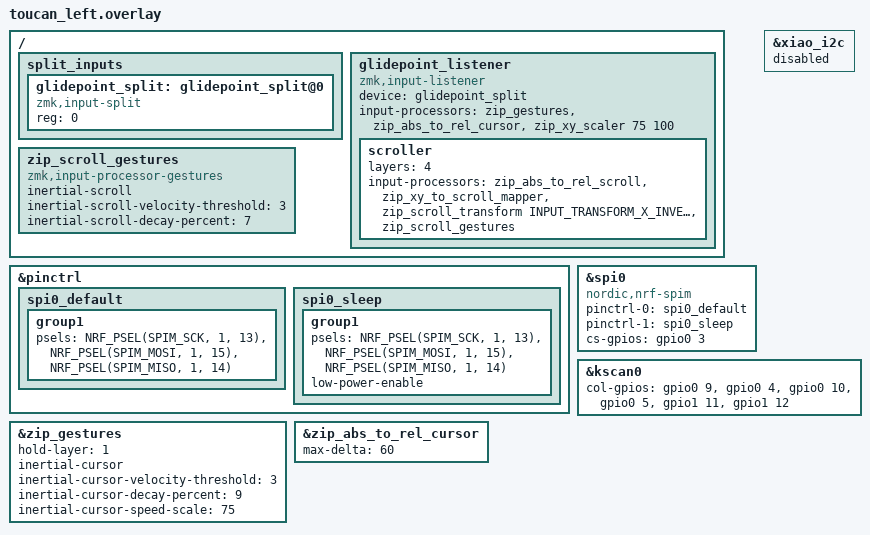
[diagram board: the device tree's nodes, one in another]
#include "toucan.dtsi"
#include <input/processors.dtsi>
#include <dt-bindings/zmk/input_transform.h>
#include <behaviors/input_processor_gestures.dtsi>
#include <behaviors/input_processor_abs_to_rel.dtsi>

&pinctrl {
    spi0_default: spi0_default {
        group1 {
            psels = <NRF_PSEL(SPIM_SCK, 1, 13)>,
                <NRF_PSEL(SPIM_MOSI, 1, 15)>,
                <NRF_PSEL(SPIM_MISO, 1, 14)>;
        };
    };

     spi0_sleep: spi0_sleep {
        group1 {
            psels = <NRF_PSEL(SPIM_SCK, 1, 13)>,
                    <NRF_PSEL(SPIM_MOSI, 1, 15)>,
                    <NRF_PSEL(SPIM_MISO, 1, 14)>;
            low-power-enable;
        };
    };

};

nice_view_spi: &spi0 {
   compatible = "nordic,nrf-spim";
   pinctrl-0 = <&spi0_default>;
   pinctrl-1 = <&spi0_sleep>;
   pinctrl-names = "default", "sleep";
   cs-gpios = <&gpio0 3 GPIO_ACTIVE_HIGH>;
};

&xiao_i2c {
    status = "disabled";
};

&kscan0 {
    col-gpios
    = <&gpio0 9 GPIO_ACTIVE_HIGH>
    , <&gpio0 4 GPIO_ACTIVE_HIGH>
    , <&gpio0 10 GPIO_ACTIVE_HIGH>
    , <&gpio0 5 GPIO_ACTIVE_HIGH>
    , <&gpio1 11 GPIO_ACTIVE_HIGH>
    , <&gpio1 12 GPIO_ACTIVE_HIGH>
    ;
};

/ {
    split_inputs {
        #address-cells = <1>;
        #size-cells = <0>;

        glidepoint_split: glidepoint_split@0 {
            compatible = "zmk,input-split";
            reg = <0>;
        };
    };

    glidepoint_listener: glidepoint_listener {
        compatible = "zmk,input-listener";
        status = "okay";
        device = <&glidepoint_split>;
        input-processors = <
            &zip_gestures
            &zip_abs_to_rel_cursor
            &zip_xy_scaler 75 100
        >;
        scroller {
            layers = <4>;
            input-processors = <
                &zip_abs_to_rel_scroll
                &zip_xy_to_scroll_mapper
                &zip_scroll_transform INPUT_TRANSFORM_X_INVERT
                &zip_scroll_gestures
            >;
        };
    };
};

&zip_gestures {
    hold-layer = <1>;
    inertial-cursor;
    inertial-cursor-velocity-threshold = <3>;
    inertial-cursor-decay-percent = <9>;
    inertial-cursor-speed-scale = <75>;
};

&zip_abs_to_rel_cursor {
    max-delta = <60>;
};

/ {
    zip_scroll_gestures: zip_scroll_gestures {
        compatible = "zmk,input-processor-gestures";
        #input-processor-cells = <0>;
        status = "okay";
        inertial-scroll;
        inertial-scroll-velocity-threshold = <3>;
        inertial-scroll-decay-percent = <7>;
    };
};
